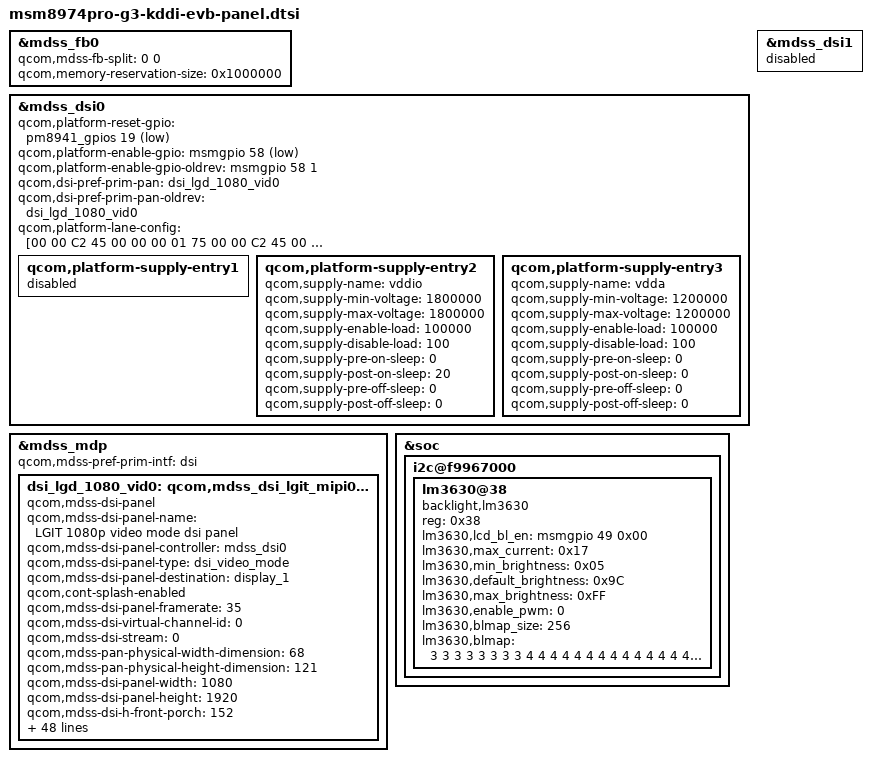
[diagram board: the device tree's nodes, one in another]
/* Copyright (c) 2013, LGE Electronics. All rights reserved.
 *
 * This program is free software; you can redistribute it and/or modify
 * it under the terms of the GNU General Public License version 2 and
 * only version 2 as published by the Free Software Foundation.
 *
 * This program is distributed in the hope that it will be useful,
 * but WITHOUT ANY WARRANTY; without even the implied warranty of
 * MERCHANTABILITY or FITNESS FOR A PARTICULAR PURPOSE.  See the
 * GNU General Public License for more details.
 */

&mdss_fb0 {
	qcom,mdss-fb-split = <0 0>;
	qcom,memory-reservation-size = <0x1000000>;
};


&mdss_dsi0 {

	qcom,platform-reset-gpio = <&pm8941_gpios 19 1>;
	qcom,platform-enable-gpio = <&msmgpio 58 1>;
	qcom,platform-enable-gpio-oldrev = <&msmgpio 58 1>;
	qcom,dsi-pref-prim-pan = <&dsi_lgd_1080_vid0>;
	qcom,dsi-pref-prim-pan-oldrev = <&dsi_lgd_1080_vid0>;
	qcom,platform-lane-config = [00 00 C2 45 00 00 00 01 75
	        00 00 C2 45 00 00 00 01 75
    	    00 00 C2 45 00 00 00 01 75
        	00 00 C2 45 00 00 00 01 75
        	00 02 45 00 00 00 00 01 97];
	qcom,platform-supply-entry1 {
		status = "disable";
	};

	qcom,platform-supply-entry2 {
		qcom,supply-name = "vddio";
		qcom,supply-min-voltage = <1800000>;
		qcom,supply-max-voltage = <1800000>;
		qcom,supply-enable-load = <100000>;
		qcom,supply-disable-load = <100>;
		qcom,supply-pre-on-sleep = <0>;
		qcom,supply-post-on-sleep = <20>;
		qcom,supply-pre-off-sleep = <0>;
		qcom,supply-post-off-sleep = <0>;
	};

	qcom,platform-supply-entry3 {
		qcom,supply-name = "vdda";
		qcom,supply-min-voltage = <1200000>;
		qcom,supply-max-voltage = <1200000>;
		qcom,supply-enable-load = <100000>;
		qcom,supply-disable-load = <100>;
		qcom,supply-pre-on-sleep = <0>;
		qcom,supply-post-on-sleep = <0>;
		qcom,supply-pre-off-sleep = <0>;
		qcom,supply-post-off-sleep = <0>;
	};
};

&mdss_dsi1 {
	status = "disable";
};
&mdss_mdp {
	qcom,mdss-pref-prim-intf = "dsi";

	dsi_lgd_1080_vid0: qcom,mdss_dsi_lgit_mipi0_video {
		compatible = "qcom,mdss-dsi-panel";
		qcom,mdss-dsi-panel-name = "LGIT 1080p video mode dsi panel";
		qcom,mdss-dsi-panel-controller = <&mdss_dsi0>;
		qcom,mdss-dsi-panel-type = "dsi_video_mode";
		qcom,mdss-dsi-panel-destination = "display_1";
		qcom,cont-splash-enabled;
		qcom,mdss-dsi-panel-framerate = <35>;
		qcom,mdss-dsi-virtual-channel-id = <0>;
		qcom,mdss-dsi-stream = <0>;
		qcom,mdss-pan-physical-width-dimension = <68>;
		qcom,mdss-pan-physical-height-dimension = <121>;
		qcom,mdss-dsi-panel-width = <1080>;
		qcom,mdss-dsi-panel-height = <1920>;
		qcom,mdss-dsi-h-front-porch = <152>;
		qcom,mdss-dsi-h-back-porch = <144>;
		qcom,mdss-dsi-h-pulse-width = <4>;
		qcom,mdss-dsi-h-sync-skew = <0>;
		qcom,mdss-dsi-v-back-porch = <9>;
		qcom,mdss-dsi-v-front-porch = <3>;
		qcom,mdss-dsi-v-pulse-width = <1>;
		qcom,mdss-dsi-h-left-border = <0>;
		qcom,mdss-dsi-h-right-border = <0>;
		qcom,mdss-dsi-v-top-border = <0>;
		qcom,mdss-dsi-v-bottom-border = <0>;
		qcom,mdss-dsi-bpp = <24>;
		qcom,mdss-dsi-color-order = <0>;
		qcom,mdss-dsi-underflow-color = <0xff>;
		qcom,mdss-dsi-border-color = <0>;
		qcom,mdss-dsi-reset-sequence = <1 20>, <0 10>, <1 10>;
		lge,mdss-set-address-mode-command = [
			15 01 00 00 00 00 02 36 40];
		qcom,mdss-dsi-on-command = [
			/*mcap_setting*/
			29 01 00 00 00 00 02 b0 04  // changed it to 29
			/*nop_command*/
			05 01 00 00 00 00 01 00
			05 01 00 00 00 00 01 00
			/*interface setting*/
			29 01 00 00 00 00 07 b3
			14 00 00 00 00 00
			/*dsi_ctrl*/
			29 01 00 00 00 00 03 b6
			3a d3
			/*display setting_1*/
			29 01 00 00 00 00 23 c1
			84 60 50 eb ff
			6f ce ff ff 0f
			01 58 73 ae 31
			20 c6 ff ff 1f
			f3 ff 5f 10 10
			10 10 00 00 00
			22 02 02 00
			/*display setting_2*/
			29 01 00 00 00 00 08 c2
			32 f7 80 0a 08
			00 00
			/*vsync_setting*/
			29 01 00 00 00 00 04 c3
			01 00 00
			/*source timing setting*/
			29 01 00 00 00 00 17 c4
			70 00 00 00 07
			03 03 07 07 0c
			06 00 00 00 00
			07 03 03 07 07
			0c 06
			/*ltps timing setting*/
			29 01 00 00 00 00 29 c6
			00 69 00 69 00
			69 00 00 00 00
			00 69 00 69 00
			69 10 19 07 00
			01 00 69 00 69
			00 69 00 00 00
			00 00 69 00 69
			00 69 10 19 07
			/*gamma setting a*/
			29 01 00 00 00 00 19 c7
			00 09 14 23 30
			48 3d 52 5f 67
			6b 70 00 09 14
			23 30 48 3d 52
			5f 67 6b 70
			/*gamma setting b*/
			29 01 00 00 00 00 19 c8
			00 09 14 23 30
			48 3d 52 5f 67
			6b 70 00 09 14
			23 30 48 3d 52
			5f 67 6b 70
			/*gamma setting c*/
			29 01 00 00 00 00 19 c9
			00 09 14 23 30
			48 3d 52 5f 67
			6b 70 00 09 14
			23 30 48 3d 52
			5f 67 6b 70
			/*panel_pin_control*/
			29 01 00 00 00 00 0a cb
			31 fc 3f 8c 00
			00 00 00 c0
			/*panel_interface_ctrl*/
			29 01 00 00 00 00 02 cc
			09
			/*pwr_setting_chg_pump*/
			29 01 00 00 00 00 0f d0
			00 00 19 18 99
			99 19 01 89 00
			55 19 99 01
			/*pwr_setting_internal_pwr*/
			29 01 00 00 00 00 1b d3
			1b 33 bb cc c4
			33 33 33 00 01
			00 a0 d8 a0 0d
			39 33 44 22 70
			02 39 03 3d bf
			00
			/*vcom_settting*/
			29 01 00 00 00 00 08 d5
			06 00 00 01 2c
			01 2c
			/*vcom_settting*/
			29 01 00 00 00 00 08 d5
			06 00 00 01 2c
			01 2c
			/*set_address_mode*/
			15 01 00 00 00 00 02 36
			40
			/*color_enhancement*/
			29 01 00 00 00 00 21 ca
			01 70 90 a0 b0
			98 90 90 3f 3f
			80 78 08 38 08
			3f 08 90 0c 0C
			0a 06 04 04 00
			c8 10 10 3f 3f
			3f 3f
			/*auto contrast*/
			29 01 00 00 00 00 07 d8
			00 80 80 40 42
			55
			/*sharpening control*/
			29 01 00 00 00 00 03 dd
			01 95
			/*display_on*/
			05 01 00 00 00 00 01 29
			/*exit_sleep_mode*/
			05 01 00 00 64 00 01 11];

		qcom,mdss-dsi-off-command = [
			29 01 00 00 00 00 08 d5
			06 00 00 00 48
			00 48
			29 01 00 00 0d 00 08 d5
			06 00 00 00 48
			00 48
			05 01 00 00 14 00 01 28
			05 01 00 00 64 00 01 10];

		qcom,mdss-dsi-on-command-state = "dsi_lp_mode";
		qcom,mdss-dsi-off-command-state = "dsi_hs_mode";
		qcom,mdss-dsi-h-sync-pulse = <0>;
		qcom,mdss-dsi-traffic-mode = <1>;
		qcom,mdss-dsi-lane-map = <0>;
		qcom,mdss-dsi-bllp-eof-power-mode;
		qcom,mdss-dsi-bllp-power-mode;
		qcom,mdss-dsi-lane-0-state;
		qcom,mdss-dsi-lane-1-state;
		qcom,mdss-dsi-lane-2-state;
		qcom,mdss-dsi-lane-3-state;

		qcom,mdss-dsi-panel-timings = [
			66 26 3a 00 41 b5
			1e 9C 41 03 04 00];
		qcom,mdss-dsi-t-clk-post = <0x21>;
		qcom,mdss-dsi-t-clk-pre = <0x3d>;
		qcom,mdss-dsi-bl-min-level = <1>;
		qcom,mdss-dsi-bl-max-level = <255>;
		qcom,mdss-dsi-dma-trigger = <4>;
		qcom,mdss-dsi-mdp-trigger = <0>;
		qcom,mdss-dsi-bl-pmic-control-type = "others";
		qcom,off-cmds-dsi-state = "dsi_hs_mode";
		qcom,panel-ief-off-cmds = [
			29 01 00 00 00 00 02 b0 04
			29 01 00 00 00 00 03 dd
			11 17
			39 01 00 00 00 00 02 51
			ff
			15 01 00 00 00 00 02 53
			2c
			15 01 00 00 00 00 02 55
			01
			39 01 00 00 00 00 02 5e
			00
			29 01 00 00 00 00 07 b8
			07 90 1e 00 40 32
			29 01 00 00 00 00 07 b9
			07 8c 3c 20 2d 87
			29 01 00 00 00 00 07 ba
			07 8c 3c 20 2d 87
			29 01 00 00 00 00 18 ce
			75 40 43 49 55
			62 71 82 94 a8
			b9 cb db e9 f5
			fc ff 04 00 04
			04 44 20
			29 01 00 00 00 00 21 ca
			01 70 8e a0 b0
			b0 a0 85 3f 3f
			10 78 08 38 08
			3f 08 90 0C 0C
			0a 06 04 04 00
			c0 10 10 3F 3F
			3F 3F
			29 01 00 00 00 00 02 b0 03
			];
		qcom,ief-off-dsi-state = "dsi_hs_mode";
		qcom,panel-ief-on-cmds = [
			29 01 00 00 00 00 02 b0 04
			29 01 00 00 00 00 03 dd
			01 95
			39 01 00 00 00 00 02 51
			ff
			15 01 00 00 00 00 02 53
			2c
			15 01 00 00 00 00 02 55
			01
			39 01 00 00 00 00 02 5e
			00
			29 01 00 00 00 00 07 b8
			07 90 1e 00 40 32
			29 01 00 00 00 00 07 b9
			07 8c 3c 20 2d 87
			29 01 00 00 00 00 07 ba
			07 8c 3c 20 2d 87
			29 01 00 00 00 00 18 ce
			75 40 43 49 55
			62 71 82 94 a8
			b9 cb db e9 f5
			fc ff 04 00 04
			04 44 20
			29 01 00 00 00 00 21 ca
			01 70 8e a0 b0
			b0 a0 85 3f 3f
			10 78 08 38 08
			3f 08 90 0C 0C
			0a 06 04 04 00
			c0 10 10 3F 3F
			3F 3F
			29 01 00 00 00 00 02 b0 03];
		qcom,ief-on-dsi-state = "dsi_hs_mode";
	};
};


&soc {
	i2c@f9967000 {
		lm3630@38 {
			compatible = "backlight,lm3630";
			status = "ok";
			reg = <0x38>;
			lm3630,lcd_bl_en = <&msmgpio 49 0x00>;
			lm3630,max_current = <0x17>;
			lm3630,min_brightness = <0x05>;
			lm3630,default_brightness = <0x9C>;
			lm3630,max_brightness = <0xFF>;
			lm3630,enable_pwm = <0>;
			lm3630,blmap_size = <256>;
			lm3630,blmap = <
				3 3 3 3 3 3 3 3 4 4 4 4 4 4 4
				4 4 4 4 4 4 4 5 5 5 5 5 5 5 5
				5 5 5 5 5 6 6 6 6 6 6 6 6 7 7
				7 8 8 8 9 9 9 9 9 10 10 10 11 11 11
				12 12 12 12 13 13 13 13 14 14 15 15 15 16 16
				17 17 17 18 18 18 19 19 20 21 22 22 23 24 24
				25 25 26 26 27 28 28 29 29 30 30 31 31 32 32
				33 34 35 35 36 36 37 38 39 39 40 41 41 42 43
				44 45 45 46 47 48 49 50 51 52 53 54 55 56 57
				58 59 60 61 62 63 64 65 66 67 68 69 70 71 72
				73 74 75 76 76 77 78 80 81 82 83 85 86 87 88
				89 90 91 93 95 96 97 99 100 102 103 104 106 107 108
				109 110 112 114 115 117 119 121 123 125 127 128 129 130 132
				133 135 136 138 139 140 142 144 146 148 150 151 153 154 156
				157 158 159 161 163 164 165 167 168 170 173 175 177 180 184
				186 188 191 194 197 199 201 203 205 207 209 211 213 215 217
				219 221 223 225 227 228 230 232 235 238 240 243 246 249 252
				255>;
		};
	};
};
